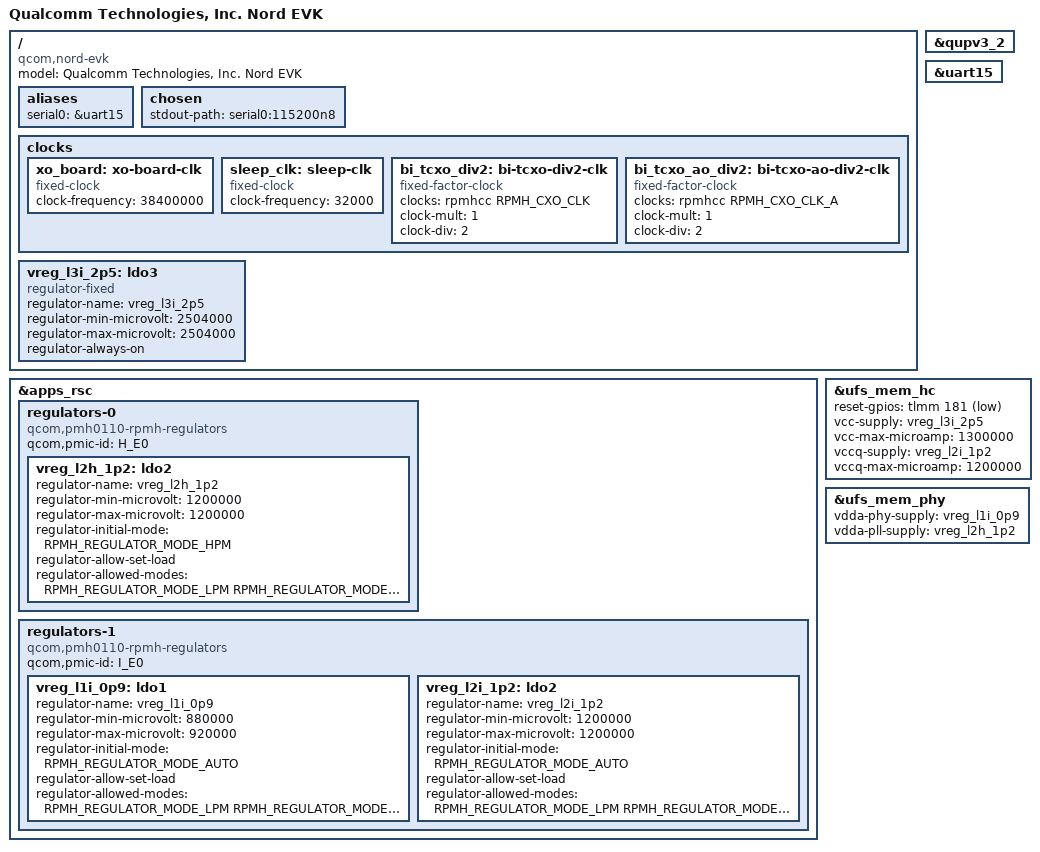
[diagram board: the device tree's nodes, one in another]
// SPDX-License-Identifier: BSD-3-Clause
/*
 * Copyright (c) 2024-2025, Qualcomm Innovation Center, Inc. All rights reserved.
 */

/dts-v1/;

#include <dt-bindings/gpio/gpio.h>
#include <dt-bindings/regulator/qcom,rpmh-regulator.h>

#include "nord-iot.dtsi"

/ {
	model = "Qualcomm Technologies, Inc. Nord EVK";
	compatible = "qcom,nord-evk", "qcom,sa8797p";

	aliases {
		serial0 = &uart15;
	};

	chosen {
		stdout-path = "serial0:115200n8";
	};

	clocks {
		xo_board: xo-board-clk {
			compatible = "fixed-clock";
			clock-frequency = <38400000>;
			#clock-cells = <0>;
		};

		sleep_clk: sleep-clk {
			compatible = "fixed-clock";
			clock-frequency = <32000>;
			#clock-cells = <0>;
		};

		bi_tcxo_div2: bi-tcxo-div2-clk {
			compatible = "fixed-factor-clock";
			#clock-cells = <0>;
			clocks = <&rpmhcc RPMH_CXO_CLK>;
			clock-mult = <1>;
			clock-div = <2>;
		};

		bi_tcxo_ao_div2: bi-tcxo-ao-div2-clk {
			compatible = "fixed-factor-clock";
			#clock-cells = <0>;
			clocks = <&rpmhcc RPMH_CXO_CLK_A>;
			clock-mult = <1>;
			clock-div = <2>;
		};
	};

	vreg_l3i_2p5: ldo3 {
		compatible = "regulator-fixed";
		regulator-name = "vreg_l3i_2p5";
		regulator-min-microvolt = <2504000>;
		regulator-max-microvolt = <2504000>;
		regulator-always-on;
	};
};

&apps_rsc {
	regulators-0 {
		compatible = "qcom,pmh0110-rpmh-regulators";
		qcom,pmic-id = "H_E0";

		vreg_l2h_1p2: ldo2 {
			regulator-name = "vreg_l2h_1p2";
			regulator-min-microvolt = <1200000>;
			regulator-max-microvolt = <1200000>;
			regulator-initial-mode = <RPMH_REGULATOR_MODE_HPM>;
			regulator-allow-set-load;
			regulator-allowed-modes = <RPMH_REGULATOR_MODE_LPM
						   RPMH_REGULATOR_MODE_HPM>;
		};
	};

	regulators-1 {
		compatible = "qcom,pmh0110-rpmh-regulators";
		qcom,pmic-id = "I_E0";

		vreg_l1i_0p9: ldo1 {
			regulator-name = "vreg_l1i_0p9";
			regulator-min-microvolt = <880000>;
			regulator-max-microvolt = <920000>;
			regulator-initial-mode = <RPMH_REGULATOR_MODE_AUTO>;
			regulator-allow-set-load;
			regulator-allowed-modes = <RPMH_REGULATOR_MODE_LPM
						   RPMH_REGULATOR_MODE_AUTO>;
		};

		vreg_l2i_1p2: ldo2 {
			regulator-name = "vreg_l2i_1p2";
			regulator-min-microvolt = <1200000>;
			regulator-max-microvolt = <1200000>;
			regulator-initial-mode = <RPMH_REGULATOR_MODE_AUTO>;
			regulator-allow-set-load;
			regulator-allowed-modes = <RPMH_REGULATOR_MODE_LPM
						   RPMH_REGULATOR_MODE_AUTO>;
		};

		/*
		vreg_l3i_2p5: ldo3 {
			regulator-name = "vreg_l3i_2p5";
			regulator-min-microvolt = <2496000>;
			regulator-max-microvolt = <2504000>;
			regulator-initial-mode = <RPMH_REGULATOR_MODE_HPM>;
			regulator-allow-set-load;
			regulator-allowed-modes = <RPMH_REGULATOR_MODE_LPM
			RPMH_REGULATOR_MODE_HPM>;
		};
		 */
	};
};

&qupv3_2 {
	status = "okay";
};

&uart15 {
	status = "okay";
};

&ufs_mem_hc {
	reset-gpios = <&tlmm 181 GPIO_ACTIVE_LOW>;
	vcc-supply = <&vreg_l3i_2p5>;
	vcc-max-microamp = <1300000>;
	vccq-supply = <&vreg_l2i_1p2>;
	vccq-max-microamp = <1200000>;
	status = "okay";
};

&ufs_mem_phy {
	vdda-phy-supply = <&vreg_l1i_0p9>;
	vdda-pll-supply = <&vreg_l2h_1p2>;
	status = "okay";
};
